# PY32F071Cxx register map
Vendor: Puya; Series: PY32F0; File version: 1.0.0
CPU: CM0+ r0p1, little endian, no MPU, no FPU, 4 interrupt priority bits
Registers are 32-bit, read-write, reset 0x0 unless marked. A register's access mark holds for its fields unless they carry their own. Offsets are from the block's base; [hi:lo] are bit positions; {n}, {i} and the like mark numbered series; 'fields as' and 'values as' point back to an identical list.

## DBGMCU — Debug support
Base 0x40015800
0x00 IDCODE ro — MCU Device ID Code Register
  [30:0] REV_ID
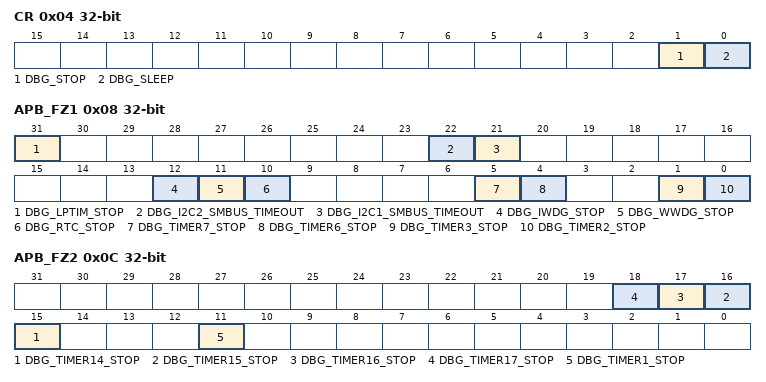
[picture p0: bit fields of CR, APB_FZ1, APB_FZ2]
0x04 CR — Debug MCU Configuration Register
  [1] DBG_STOP — Debug Stop Mode
  [0] DBG_SLEEP — Debug Sleep Mode
0x08 APB_FZ1 — APB Freeze Register1
  [31] DBG_LPTIM_STOP — Debug LPTIM stopped when Core is halted
  [22] DBG_I2C2_SMBUS_TIMEOUT ro
  [21] DBG_I2C1_SMBUS_TIMEOUT
  [12] DBG_IWDG_STOP — Debug Independent Wachdog stopped when Core is halted
  [11] DBG_WWDG_STOP — Debug Window Wachdog stopped when Core is halted
  [10] DBG_RTC_STOP — Debug RTC stopped when Core is halted
  [5] DBG_TIMER7_STOP — Debug Timer 7 stopped when Core is halted
  [4] DBG_TIMER6_STOP — Debug Timer 6 stopped when Core is halted
  [1] DBG_TIMER3_STOP — Debug Timer 3 stopped when Core is halted
  [0] DBG_TIMER2_STOP — Debug Timer 2 stopped when Core is halted
0x0C APB_FZ2 — APB Freeze Register2
  [n+1] DBG_TIMER{n}_STOP (n=14..17) — Debug Timer {n} stopped when Core is halted
  [11] DBG_TIMER1_STOP — Debug Timer 1 stopped when Core is halted

## DIV — Hardware Divider
Base 0x40023800
0x00 DEND — Dividend
0x04 SOR — Divisor
0x08 QUOT ro — Quotient
0x0C REMA ro — Remainder
0x10 SIGN — des SIGN
  [0] DIV_SIGN — des DIV_SIGN
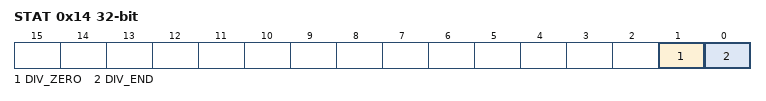
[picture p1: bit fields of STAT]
0x14 STAT — des SIGN
  [1] DIV_ZERO — des DIV_ZERO
  [0] DIV_END — des DIV_END

## DMA — Direct memory access
Base 0x40020000
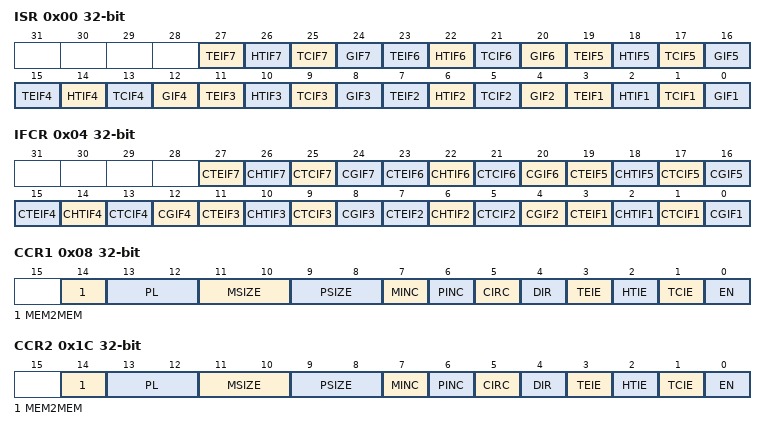
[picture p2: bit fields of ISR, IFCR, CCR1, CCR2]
0x00 ISR ro
  [4n-1] TEIF{n} (n=1..7), [4n-2] HTIF{n} (n=1..7), [4n-3] TCIF{n} (n=1..7), [4n-4] GIF{n} (n=1..7)
0x04 IFCR wo
  [4n-1] CTEIF{n} (n=1..7), [4n-2] CHTIF{n} (n=1..7), [4n-3] CTCIF{n} (n=1..7), [4n-4] CGIF{n} (n=1..7)
0x08 CCR1
  [14] MEM2MEM, [13:12] PL, [11:10] MSIZE, [9:8] PSIZE, [7] MINC, [6] PINC, [5] CIRC, [4] DIR, [3] TEIE, [2] HTIE, [1] TCIE, [0] EN
0x0C CNDTR1
  [15:0] NDT
0x10 CPAR1
  [31:0] PA
{0x0+0x14*i} CMAR{i} (i=1..7)
  [31:0] MA
0x1C CCR2
  fields as CCR1
0x20 CNDTR2
  [15:0] NDT
0x24 CPAR2
  [31:0] PA
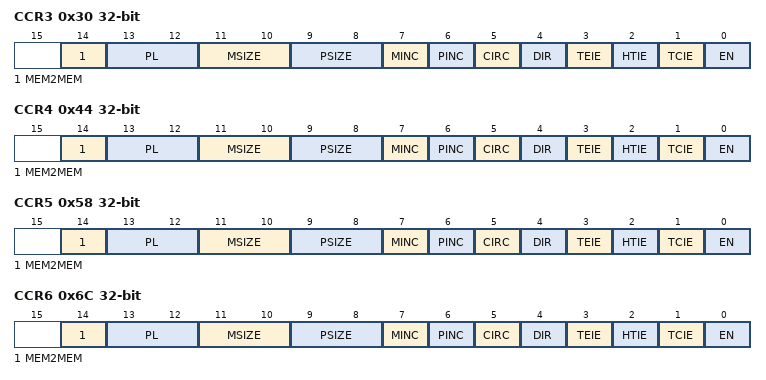
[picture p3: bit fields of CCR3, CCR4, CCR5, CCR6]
0x30 CCR3
  fields as CCR1
0x34 CNDTR3
  [15:0] NDT
0x38 CPAR3
  [31:0] PA
0x44 CCR4
  fields as CCR1
0x48 CNDTR4
  [15:0] NDT
0x4C CPAR4
  [31:0] PA
0x58 CCR5
  fields as CCR1
0x5C CNDTR5
  [15:0] NDT
0x60 CPAR5
  [31:0] PA
0x6C CCR6
  fields as CCR1
0x70 CNDTR6
  [15:0] NDT
0x74 CPAR6
  [31:0] PA
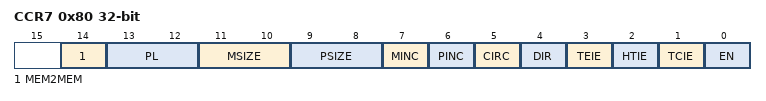
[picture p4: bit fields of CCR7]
0x80 CCR7
  fields as CCR1
0x84 CNDTR7
  [15:0] NDT
0x88 CPAR7
  [31:0] PA

## EXTI — External interrupt/event controller
Base 0x40021800
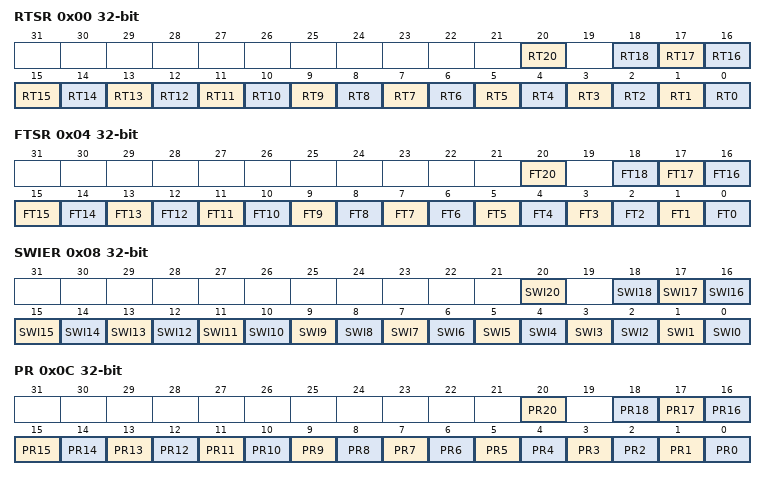
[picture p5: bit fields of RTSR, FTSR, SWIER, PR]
0x00 RTSR — EXTI rising trigger selection register
  [20] RT20 — Rising trigger event configuration bit of Configurable Event input
  [n] RT{n} (n=0..18) — Rising trigger event configuration bit of Configurable Event input
0x04 FTSR — EXTI falling trigger selection register
  [20] FT20 — Falling trigger event configuration bit of Configurable Event input
  [n] FT{n} (n=0..18) — Falling trigger event configuration bit of Configurable Event input
0x08 SWIER — EXTI software interrupt event register
  [20] SWI20 — Rising trigger event configuration bit of Configurable Event input
  [n] SWI{n} (n=0..18) — Rising trigger event configuration bit of Configurable Event input
0x0C PR — EXTI pending register
  [20] PR20 — configurable event inputs x rising edge Pending bit.
  [n] PR{n} (n=14..18) — configurable event inputs x rising edge Pending bit.
  [13] PR13 — configurable event inputs x rising edge Pending bit
  [n] PR{n} (n=0..12) — configurable event inputs x rising edge Pending bit.
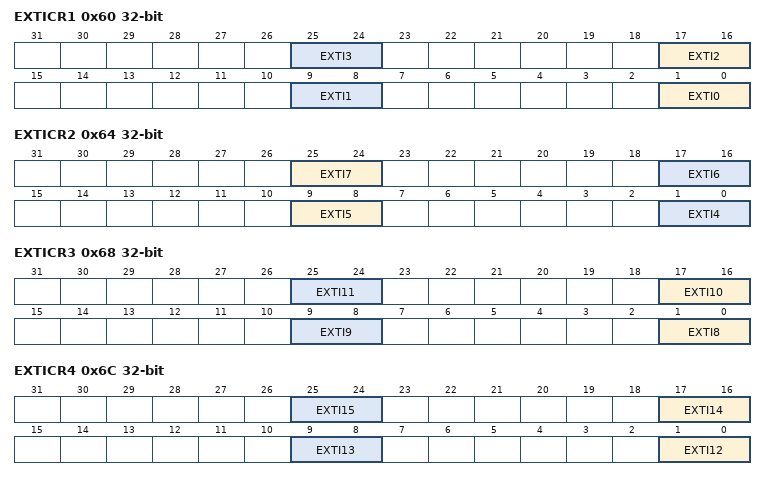
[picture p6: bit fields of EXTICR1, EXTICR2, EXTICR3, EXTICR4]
0x60 EXTICR1 — EXTI external interrupt selection register
  [all] fields
    1=0; 2=1
  [8n+1:8n] EXTI{n} (n=0..3) — GPIO port selection
0x64 EXTICR2 — EXTI external interrupt selection register
  [25:24] EXTI7 — GPIO port selection
  [17:16] EXTI6 — GPIO port selection
  [9:8] EXTI5 — GPIO port selection
  [1:0] EXTI4 — GPIO port selection
    1=0; 2=1
0x68 EXTICR3 — EXTI external interrupt selection register
  [all] fields
    1=0; 2=1
  [8n-63:8n-64] EXTI{n} (n=8..11) — GPIO port selection
0x6C EXTICR4 — EXTI external interrupt selection register
  [all] fields
    1=0; 2=1
  [8n-95:8n-96] EXTI{n} (n=12..15) — GPIO port selection
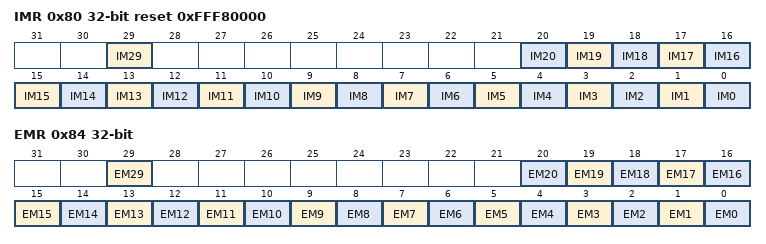
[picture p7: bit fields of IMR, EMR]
0x80 IMR reset 0xFFF80000 — EXTI CPU wakeup with interrupt mask register
  [29] IM29 — CPU wakeup with interrupt mask on event input
  [n] IM{n} (n=0..20) — CPU wakeup with interrupt mask on event input
0x84 EMR — EXTI CPU wakeup with event mask register
  [29] EM29 — CPU wakeup with event mask on event input
  [n] EM{n} (n=0..20) — CPU wakeup with event mask on event input
